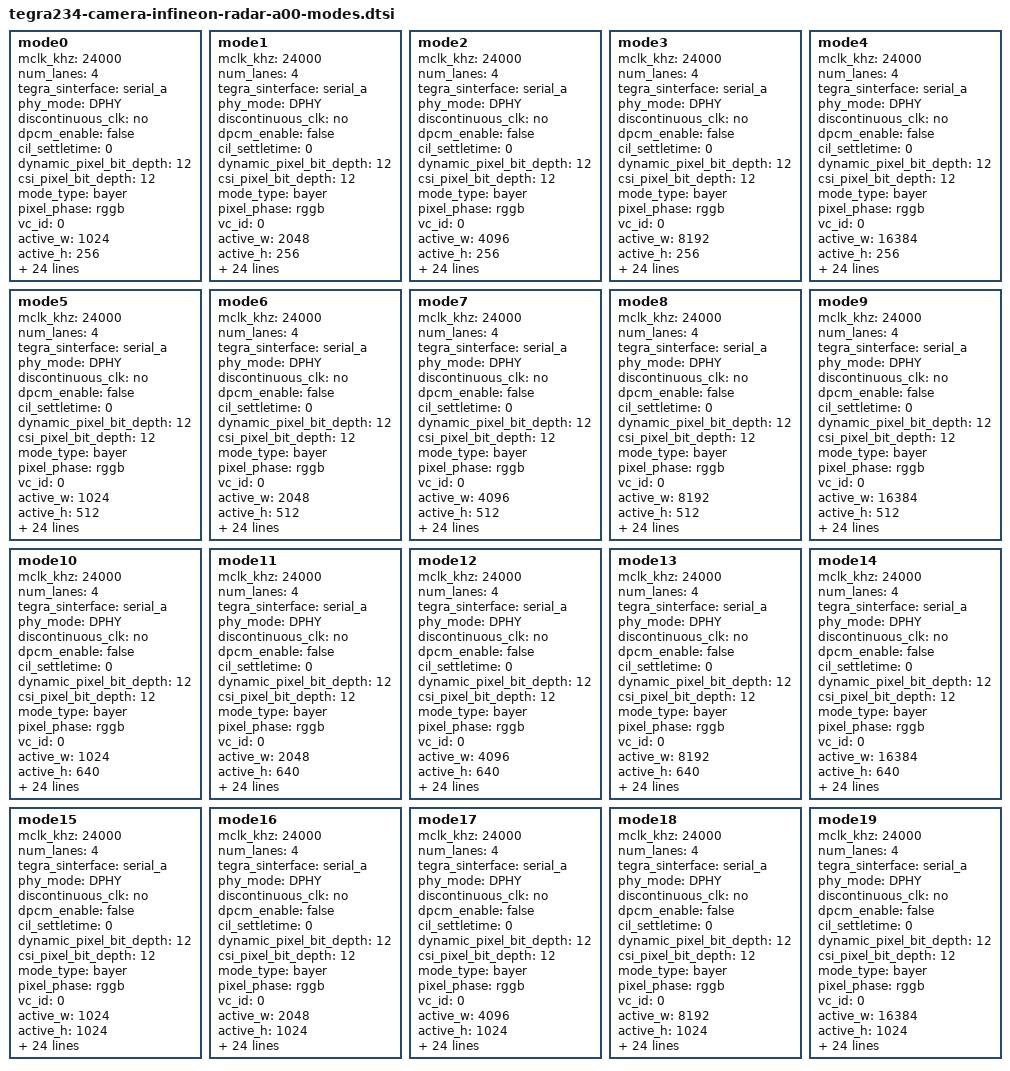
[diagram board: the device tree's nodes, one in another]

/**
* ==== Modes ====
* A modeX node is required to support v4l2 driver
* implementation with NVIDIA camera software stack
*
* == Signal properties ==
*
* phy_mode = "";
* PHY mode used by the MIPI lanes for this device
*
* tegra_sinterface = "";
* CSI Serial interface connected to tegra
* Incase of virtual HW devices, use virtual
* For SW emulated devices, use host
*
* pix_clk_hz = "";
* Sensor pixel clock used for calculations like exposure and framerate
* Not used by the camera stack if serdes_pix_clk_hz is defined
*
* serdes_pix_clk_hz = "";
* Serdes pixel clock used for calculations like exposure and framerate
* It is used when the system includes a serdes system because the data
* is received from the Deserializer
* serdes_pix_clk_hz = (deserializer output data rate in hertz) * (number of CSI lanes) / (bits per pixel)
* 
* readout_orientation = "0";
* Based on camera module orientation.
* Only change readout_orientation if you specifically
* Program a different readout order for this mode
*
* == Image format Properties ==
*
* active_w = "";
* Pixel active region width
*
* active_h = "";
* Pixel active region height
*
* pixel_t = "";
* The sensor readout pixel pattern
*
* line_length = "";
* Pixel line length (width) for sensor mode. Must be greater than or equal to active_w
*
* == Source Control Settings ==
*
* Gain factor used to convert fixed point integer to float
* Gain range [min_gain/gain_factor, max_gain/gain_factor]
* Gain step [step_gain/gain_factor is the smallest step that can be configured]
* Default gain [Default gain to be initialized for the control.
*     use min_gain_val as default for optimal results]
* Framerate factor used to convert fixed point integer to float
* Framerate range [min_framerate/framerate_factor, max_framerate/framerate_factor]
* Framerate step [step_framerate/framerate_factor is the smallest step that can be configured]
* Default Framerate [Default framerate to be initialized for the control.
*     use max_framerate to get required performance]
* Exposure factor used to convert fixed point integer to float
* For convenience use 1 sec = 1000000us as conversion factor
* Exposure range [min_exp_time/exposure_factor, max_exp_time/exposure_factor]
* Exposure step [step_exp_time/exposure_factor is the smallest step that can be configured]
* Default Exposure Time [Default exposure to be initialized for the control.
*     Set default exposure based on the default_framerate for optimal exposure settings]
*
* gain_factor = ""; (integer factor used for floating to fixed point conversion)
* min_gain_val = ""; (ceil to integer)
* max_gain_val = ""; (ceil to integer)
* step_gain_val = ""; (ceil to integer)
* default_gain = ""; (ceil to integer)
* Gain limits for mode
*
* exposure_factor = ""; (integer factor used for floating to fixed point conversion)
* min_exp_time = ""; (ceil to integer)
* max_exp_time = ""; (ceil to integer)
* step_exp_time = ""; (ceil to integer)
* default_exp_time = ""; (ceil to integer)
* Exposure Time limits for mode (sec)
*
* framerate_factor = ""; (integer factor used for floating to fixed point conversion)
* min_framerate = ""; (ceil to integer)
* max_framerate = ""; (ceil to integer)
* step_framerate = ""; (ceil to integer)
* default_framerate = ""; (ceil to integer)
* Framerate limits for mode (fps)
*
* embedded_metadata_height = "";
* Sensor embedded metadata height in units of rows.
* If sensor does not support embedded metadata value should be 0.
*/
mode0 {
    mclk_khz = "24000";
    num_lanes = "4";
    tegra_sinterface = "serial_a";
    phy_mode = "DPHY";
    discontinuous_clk = "no";
    dpcm_enable = "false";
    cil_settletime = "0";
    dynamic_pixel_bit_depth = "12";
    csi_pixel_bit_depth = "12";
    mode_type = "bayer";
    pixel_phase = "rggb";
    vc_id = "0";

    active_w = "1024";
    active_h = "256";
    readout_orientation = "0";
    line_length = "10000";
    inherent_gain = "1";
    mclk_multiplier = "14.58";
    pix_clk_hz = "400000000"; /* Not used if serdes_pix_clk_hz is defined */
    serdes_pix_clk_hz = "400000000";

    gain_factor = "10";
    min_gain_val = "10";
    max_gain_val = "110";
    step_gain_val = "1";
    default_gain = "10";

    min_hdr_ratio = "1";
    max_hdr_ratio = "1";

    framerate_factor = "1000000";
    min_framerate = "30000000"; /* 1.5 */
    max_framerate = "30000000"; /* 30 */
    step_framerate = "1";
    default_framerate= "30000000";

    exposure_factor = "1000000";
    min_exp_time = "30"; /* us */
    max_exp_time = "33000"; /* us */
    step_exp_time = "1";
    default_exp_time = "30000";/* us */
    embedded_metadata_height = "0";
};

mode1 {
    mclk_khz = "24000";
    num_lanes = "4";
    tegra_sinterface = "serial_a";
    phy_mode = "DPHY";
    discontinuous_clk = "no";
    dpcm_enable = "false";
    cil_settletime = "0";
    dynamic_pixel_bit_depth = "12";
    csi_pixel_bit_depth = "12";
    mode_type = "bayer";
    pixel_phase = "rggb";
    vc_id = "0";

    active_w = "2048";
    active_h = "256";
    readout_orientation = "0";
    line_length = "10000";
    inherent_gain = "1";
    mclk_multiplier = "14.58";
    pix_clk_hz = "400000000"; /* Not used if serdes_pix_clk_hz is defined */
    serdes_pix_clk_hz = "400000000";

    gain_factor = "10";
    min_gain_val = "10";
    max_gain_val = "110";
    step_gain_val = "1";
    default_gain = "10";

    min_hdr_ratio = "1";
    max_hdr_ratio = "1";

    framerate_factor = "1000000";
    min_framerate = "30000000"; /* 1.5 */
    max_framerate = "30000000"; /* 30 */
    step_framerate = "1";
    default_framerate= "30000000";

    exposure_factor = "1000000";
    min_exp_time = "30"; /* us */
    max_exp_time = "33000"; /* us */
    step_exp_time = "1";
    default_exp_time = "30000";/* us */
    embedded_metadata_height = "0";
};

mode2 {
    mclk_khz = "24000";
    num_lanes = "4";
    tegra_sinterface = "serial_a";
    phy_mode = "DPHY";
    discontinuous_clk = "no";
    dpcm_enable = "false";
    cil_settletime = "0";
    dynamic_pixel_bit_depth = "12";
    csi_pixel_bit_depth = "12";
    mode_type = "bayer";
    pixel_phase = "rggb";
    vc_id = "0";

    active_w = "4096";
    active_h = "256";
    readout_orientation = "0";
    line_length = "10000";
    inherent_gain = "1";
    mclk_multiplier = "14.58";
    pix_clk_hz = "400000000"; /* Not used if serdes_pix_clk_hz is defined */
    serdes_pix_clk_hz = "400000000";

    gain_factor = "10";
    min_gain_val = "10";
    max_gain_val = "110";
    step_gain_val = "1";
    default_gain = "10";

    min_hdr_ratio = "1";
    max_hdr_ratio = "1";

    framerate_factor = "1000000";
    min_framerate = "30000000"; /* 1.5 */
    max_framerate = "30000000"; /* 30 */
    step_framerate = "1";
    default_framerate= "30000000";

    exposure_factor = "1000000";
    min_exp_time = "30"; /* us */
    max_exp_time = "33000"; /* us */
    step_exp_time = "1";
    default_exp_time = "30000";/* us */
    embedded_metadata_height = "0";
};

mode3 {
    mclk_khz = "24000";
    num_lanes = "4";
    tegra_sinterface = "serial_a";
    phy_mode = "DPHY";
    discontinuous_clk = "no";
    dpcm_enable = "false";
    cil_settletime = "0";
    dynamic_pixel_bit_depth = "12";
    csi_pixel_bit_depth = "12";
    mode_type = "bayer";
    pixel_phase = "rggb";
    vc_id = "0";

    active_w = "8192";
    active_h = "256";
    readout_orientation = "0";
    line_length = "10000";
    inherent_gain = "1";
    mclk_multiplier = "14.58";
    pix_clk_hz = "400000000"; /* Not used if serdes_pix_clk_hz is defined */
    serdes_pix_clk_hz = "400000000";

    gain_factor = "10";
    min_gain_val = "10";
    max_gain_val = "110";
    step_gain_val = "1";
    default_gain = "10";

    min_hdr_ratio = "1";
    max_hdr_ratio = "1";

    framerate_factor = "1000000";
    min_framerate = "30000000"; /* 1.5 */
    max_framerate = "30000000"; /* 30 */
    step_framerate = "1";
    default_framerate= "30000000";

    exposure_factor = "1000000";
    min_exp_time = "30"; /* us */
    max_exp_time = "33000"; /* us */
    step_exp_time = "1";
    default_exp_time = "30000";/* us */
    embedded_metadata_height = "0";
};

mode4 {
    mclk_khz = "24000";
    num_lanes = "4";
    tegra_sinterface = "serial_a";
    phy_mode = "DPHY";
    discontinuous_clk = "no";
    dpcm_enable = "false";
    cil_settletime = "0";
    dynamic_pixel_bit_depth = "12";
    csi_pixel_bit_depth = "12";
    mode_type = "bayer";
    pixel_phase = "rggb";
    vc_id = "0";

    active_w = "16384";
    active_h = "256";
    readout_orientation = "0";
    line_length = "16384";
    inherent_gain = "1";
    mclk_multiplier = "14.58";
    pix_clk_hz = "400000000"; /* Not used if serdes_pix_clk_hz is defined */
    serdes_pix_clk_hz = "400000000";

    gain_factor = "10";
    min_gain_val = "10";
    max_gain_val = "110";
    step_gain_val = "1";
    default_gain = "10";

    min_hdr_ratio = "1";
    max_hdr_ratio = "1";

    framerate_factor = "1000000";
    min_framerate = "30000000"; /* 1.5 */
    max_framerate = "30000000"; /* 30 */
    step_framerate = "1";
    default_framerate= "30000000";

    exposure_factor = "1000000";
    min_exp_time = "30"; /* us */
    max_exp_time = "33000"; /* us */
    step_exp_time = "1";
    default_exp_time = "30000";/* us */
    embedded_metadata_height = "0";
};

mode5 {
    mclk_khz = "24000";
    num_lanes = "4";
    tegra_sinterface = "serial_a";
    phy_mode = "DPHY";
    discontinuous_clk = "no";
    dpcm_enable = "false";
    cil_settletime = "0";
    dynamic_pixel_bit_depth = "12";
    csi_pixel_bit_depth = "12";
    mode_type = "bayer";
    pixel_phase = "rggb";
    vc_id = "0";

    active_w = "1024";
    active_h = "512";
    readout_orientation = "0";
    line_length = "10000";
    inherent_gain = "1";
    mclk_multiplier = "14.58";
    pix_clk_hz = "400000000"; /* Not used if serdes_pix_clk_hz is defined */
    serdes_pix_clk_hz = "400000000";

    gain_factor = "10";
    min_gain_val = "10";
    max_gain_val = "110";
    step_gain_val = "1";
    default_gain = "10";

    min_hdr_ratio = "1";
    max_hdr_ratio = "1";

    framerate_factor = "1000000";
    min_framerate = "30000000"; /* 1.5 */
    max_framerate = "30000000"; /* 30 */
    step_framerate = "1";
    default_framerate= "30000000";

    exposure_factor = "1000000";
    min_exp_time = "30"; /* us */
    max_exp_time = "33000"; /* us */
    step_exp_time = "1";
    default_exp_time = "30000";/* us */
    embedded_metadata_height = "0";
};

mode6 {
    mclk_khz = "24000";
    num_lanes = "4";
    tegra_sinterface = "serial_a";
    phy_mode = "DPHY";
    discontinuous_clk = "no";
    dpcm_enable = "false";
    cil_settletime = "0";
    dynamic_pixel_bit_depth = "12";
    csi_pixel_bit_depth = "12";
    mode_type = "bayer";
    pixel_phase = "rggb";
    vc_id = "0";

    active_w = "2048";
    active_h = "512";
    readout_orientation = "0";
    line_length = "10000";
    inherent_gain = "1";
    mclk_multiplier = "14.58";
    pix_clk_hz = "400000000"; /* Not used if serdes_pix_clk_hz is defined */
    serdes_pix_clk_hz = "400000000";

    gain_factor = "10";
    min_gain_val = "10";
    max_gain_val = "110";
    step_gain_val = "1";
    default_gain = "10";

    min_hdr_ratio = "1";
    max_hdr_ratio = "1";

    framerate_factor = "1000000";
    min_framerate = "30000000"; /* 1.5 */
    max_framerate = "30000000"; /* 30 */
    step_framerate = "1";
    default_framerate= "30000000";

    exposure_factor = "1000000";
    min_exp_time = "30"; /* us */
    max_exp_time = "33000"; /* us */
    step_exp_time = "1";
    default_exp_time = "30000";/* us */
    embedded_metadata_height = "0";
};

mode7 {
    mclk_khz = "24000";
    num_lanes = "4";
    tegra_sinterface = "serial_a";
    phy_mode = "DPHY";
    discontinuous_clk = "no";
    dpcm_enable = "false";
    cil_settletime = "0";
    dynamic_pixel_bit_depth = "12";
    csi_pixel_bit_depth = "12";
    mode_type = "bayer";
    pixel_phase = "rggb";
    vc_id = "0";

    active_w = "4096";
    active_h = "512";
    readout_orientation = "0";
    line_length = "10000";
    inherent_gain = "1";
    mclk_multiplier = "14.58";
    pix_clk_hz = "400000000"; /* Not used if serdes_pix_clk_hz is defined */
    serdes_pix_clk_hz = "400000000";

    gain_factor = "10";
    min_gain_val = "10";
    max_gain_val = "110";
    step_gain_val = "1";
    default_gain = "10";

    min_hdr_ratio = "1";
    max_hdr_ratio = "1";

    framerate_factor = "1000000";
    min_framerate = "30000000"; /* 1.5 */
    max_framerate = "30000000"; /* 30 */
    step_framerate = "1";
    default_framerate= "30000000";

    exposure_factor = "1000000";
    min_exp_time = "30"; /* us */
    max_exp_time = "33000"; /* us */
    step_exp_time = "1";
    default_exp_time = "30000";/* us */
    embedded_metadata_height = "0";
};

mode8 {
    mclk_khz = "24000";
    num_lanes = "4";
    tegra_sinterface = "serial_a";
    phy_mode = "DPHY";
    discontinuous_clk = "no";
    dpcm_enable = "false";
    cil_settletime = "0";
    dynamic_pixel_bit_depth = "12";
    csi_pixel_bit_depth = "12";
    mode_type = "bayer";
    pixel_phase = "rggb";
    vc_id = "0";

    active_w = "8192";
    active_h = "512";
    readout_orientation = "0";
    line_length = "10000";
    inherent_gain = "1";
    mclk_multiplier = "14.58";
    pix_clk_hz = "400000000"; /* Not used if serdes_pix_clk_hz is defined */
    serdes_pix_clk_hz = "400000000";

    gain_factor = "10";
    min_gain_val = "10";
    max_gain_val = "110";
    step_gain_val = "1";
    default_gain = "10";

    min_hdr_ratio = "1";
    max_hdr_ratio = "1";

    framerate_factor = "1000000";
    min_framerate = "30000000"; /* 1.5 */
    max_framerate = "30000000"; /* 30 */
    step_framerate = "1";
    default_framerate= "30000000";

    exposure_factor = "1000000";
    min_exp_time = "30"; /* us */
    max_exp_time = "33000"; /* us */
    step_exp_time = "1";
    default_exp_time = "30000";/* us */
    embedded_metadata_height = "0";
};

mode9 {
    mclk_khz = "24000";
    num_lanes = "4";
    tegra_sinterface = "serial_a";
    phy_mode = "DPHY";
    discontinuous_clk = "no";
    dpcm_enable = "false";
    cil_settletime = "0";
    dynamic_pixel_bit_depth = "12";
    csi_pixel_bit_depth = "12";
    mode_type = "bayer";
    pixel_phase = "rggb";
    vc_id = "0";

    active_w = "16384";
    active_h = "512";
    readout_orientation = "0";
    line_length = "16384";
    inherent_gain = "1";
    mclk_multiplier = "14.58";
    pix_clk_hz = "400000000"; /* Not used if serdes_pix_clk_hz is defined */
    serdes_pix_clk_hz = "400000000";

    gain_factor = "10";
    min_gain_val = "10";
    max_gain_val = "110";
    step_gain_val = "1";
    default_gain = "10";

    min_hdr_ratio = "1";
    max_hdr_ratio = "1";

    framerate_factor = "1000000";
    min_framerate = "30000000"; /* 1.5 */
    max_framerate = "30000000"; /* 30 */
    step_framerate = "1";
    default_framerate= "30000000";

    exposure_factor = "1000000";
    min_exp_time = "30"; /* us */
    max_exp_time = "33000"; /* us */
    step_exp_time = "1";
    default_exp_time = "30000";/* us */
    embedded_metadata_height = "0";
};

mode10 {
    mclk_khz = "24000";
    num_lanes = "4";
    tegra_sinterface = "serial_a";
    phy_mode = "DPHY";
    discontinuous_clk = "no";
    dpcm_enable = "false";
    cil_settletime = "0";
    dynamic_pixel_bit_depth = "12";
    csi_pixel_bit_depth = "12";
    mode_type = "bayer";
    pixel_phase = "rggb";
    vc_id = "0";

    active_w = "1024";
    active_h = "640";
    readout_orientation = "0";
    line_length = "10000";
    inherent_gain = "1";
    mclk_multiplier = "14.58";
    pix_clk_hz = "400000000"; /* Not used if serdes_pix_clk_hz is defined */
    serdes_pix_clk_hz = "400000000";

    gain_factor = "10";
    min_gain_val = "10";
    max_gain_val = "110";
    step_gain_val = "1";
    default_gain = "10";

    min_hdr_ratio = "1";
    max_hdr_ratio = "1";

    framerate_factor = "1000000";
    min_framerate = "30000000"; /* 1.5 */
    max_framerate = "30000000"; /* 30 */
    step_framerate = "1";
    default_framerate= "30000000";

    exposure_factor = "1000000";
    min_exp_time = "30"; /* us */
    max_exp_time = "33000"; /* us */
    step_exp_time = "1";
    default_exp_time = "30000";/* us */
    embedded_metadata_height = "0";
};

mode11 {
    mclk_khz = "24000";
    num_lanes = "4";
    tegra_sinterface = "serial_a";
    phy_mode = "DPHY";
    discontinuous_clk = "no";
    dpcm_enable = "false";
    cil_settletime = "0";
    dynamic_pixel_bit_depth = "12";
    csi_pixel_bit_depth = "12";
    mode_type = "bayer";
    pixel_phase = "rggb";
    vc_id = "0";

    active_w = "2048";
    active_h = "640";
    readout_orientation = "0";
    line_length = "10000";
    inherent_gain = "1";
    mclk_multiplier = "14.58";
    pix_clk_hz = "400000000"; /* Not used if serdes_pix_clk_hz is defined */
    serdes_pix_clk_hz = "400000000";

    gain_factor = "10";
    min_gain_val = "10";
    max_gain_val = "110";
    step_gain_val = "1";
    default_gain = "10";

    min_hdr_ratio = "1";
    max_hdr_ratio = "1";

    framerate_factor = "1000000";
    min_framerate = "30000000"; /* 1.5 */
    max_framerate = "30000000"; /* 30 */
    step_framerate = "1";
    default_framerate= "30000000";

    exposure_factor = "1000000";
    min_exp_time = "30"; /* us */
    max_exp_time = "33000"; /* us */
    step_exp_time = "1";
    default_exp_time = "30000";/* us */
    embedded_metadata_height = "0";
};

mode12 {
    mclk_khz = "24000";
    num_lanes = "4";
    tegra_sinterface = "serial_a";
    phy_mode = "DPHY";
    discontinuous_clk = "no";
    dpcm_enable = "false";
    cil_settletime = "0";
    dynamic_pixel_bit_depth = "12";
    csi_pixel_bit_depth = "12";
    mode_type = "bayer";
    pixel_phase = "rggb";
    vc_id = "0";

    active_w = "4096";
    active_h = "640";
    readout_orientation = "0";
    line_length = "10000";
    inherent_gain = "1";
    mclk_multiplier = "14.58";
    pix_clk_hz = "400000000"; /* Not used if serdes_pix_clk_hz is defined */
    serdes_pix_clk_hz = "400000000";

    gain_factor = "10";
    min_gain_val = "10";
    max_gain_val = "110";
    step_gain_val = "1";
    default_gain = "10";

    min_hdr_ratio = "1";
    max_hdr_ratio = "1";

    framerate_factor = "1000000";
    min_framerate = "30000000"; /* 1.5 */
    max_framerate = "30000000"; /* 30 */
    step_framerate = "1";
    default_framerate= "30000000";

    exposure_factor = "1000000";
    min_exp_time = "30"; /* us */
    max_exp_time = "33000"; /* us */
    step_exp_time = "1";
    default_exp_time = "30000";/* us */
    embedded_metadata_height = "0";
};

mode13 {
    mclk_khz = "24000";
    num_lanes = "4";
    tegra_sinterface = "serial_a";
    phy_mode = "DPHY";
    discontinuous_clk = "no";
    dpcm_enable = "false";
    cil_settletime = "0";
    dynamic_pixel_bit_depth = "12";
    csi_pixel_bit_depth = "12";
    mode_type = "bayer";
    pixel_phase = "rggb";
    vc_id = "0";

    active_w = "8192";
    active_h = "640";
    readout_orientation = "0";
    line_length = "10000";
    inherent_gain = "1";
    mclk_multiplier = "14.58";
    pix_clk_hz = "400000000"; /* Not used if serdes_pix_clk_hz is defined */
    serdes_pix_clk_hz = "400000000";

    gain_factor = "10";
    min_gain_val = "10";
    max_gain_val = "110";
    step_gain_val = "1";
    default_gain = "10";

    min_hdr_ratio = "1";
    max_hdr_ratio = "1";

    framerate_factor = "1000000";
    min_framerate = "30000000"; /* 1.5 */
    max_framerate = "30000000"; /* 30 */
    step_framerate = "1";
    default_framerate= "30000000";

    exposure_factor = "1000000";
    min_exp_time = "30"; /* us */
    max_exp_time = "33000"; /* us */
    step_exp_time = "1";
    default_exp_time = "30000";/* us */
    embedded_metadata_height = "0";
};

mode14 {
    mclk_khz = "24000";
    num_lanes = "4";
    tegra_sinterface = "serial_a";
    phy_mode = "DPHY";
    discontinuous_clk = "no";
    dpcm_enable = "false";
    cil_settletime = "0";
    dynamic_pixel_bit_depth = "12";
    csi_pixel_bit_depth = "12";
    mode_type = "bayer";
    pixel_phase = "rggb";
    vc_id = "0";

    active_w = "16384";
    active_h = "640";
    readout_orientation = "0";
    line_length = "16384";
    inherent_gain = "1";
    mclk_multiplier = "14.58";
    pix_clk_hz = "400000000"; /* Not used if serdes_pix_clk_hz is defined */
    serdes_pix_clk_hz = "400000000";

    gain_factor = "10";
    min_gain_val = "10";
    max_gain_val = "110";
    step_gain_val = "1";
    default_gain = "10";

    min_hdr_ratio = "1";
    max_hdr_ratio = "1";

    framerate_factor = "1000000";
    min_framerate = "30000000"; /* 1.5 */
    max_framerate = "30000000"; /* 30 */
    step_framerate = "1";
    default_framerate= "30000000";

    exposure_factor = "1000000";
    min_exp_time = "30"; /* us */
    max_exp_time = "33000"; /* us */
    step_exp_time = "1";
    default_exp_time = "30000";/* us */
    embedded_metadata_height = "0";
};

mode15 {
    mclk_khz = "24000";
    num_lanes = "4";
    tegra_sinterface = "serial_a";
    phy_mode = "DPHY";
    discontinuous_clk = "no";
    dpcm_enable = "false";
    cil_settletime = "0";
    dynamic_pixel_bit_depth = "12";
    csi_pixel_bit_depth = "12";
    mode_type = "bayer";
    pixel_phase = "rggb";
    vc_id = "0";

    active_w = "1024";
    active_h = "1024";
    readout_orientation = "0";
    line_length = "10000";
    inherent_gain = "1";
    mclk_multiplier = "14.58";
    pix_clk_hz = "400000000"; /* Not used if serdes_pix_clk_hz is defined */
    serdes_pix_clk_hz = "400000000";

    gain_factor = "10";
    min_gain_val = "10";
    max_gain_val = "110";
    step_gain_val = "1";
    default_gain = "10";

    min_hdr_ratio = "1";
    max_hdr_ratio = "1";

    framerate_factor = "1000000";
    min_framerate = "30000000"; /* 1.5 */
    max_framerate = "30000000"; /* 30 */
    step_framerate = "1";
    default_framerate= "30000000";

    exposure_factor = "1000000";
    min_exp_time = "30"; /* us */
    max_exp_time = "33000"; /* us */
    step_exp_time = "1";
    default_exp_time = "30000";/* us */
    embedded_metadata_height = "0";
};

mode16 {
    mclk_khz = "24000";
    num_lanes = "4";
    tegra_sinterface = "serial_a";
    phy_mode = "DPHY";
    discontinuous_clk = "no";
    dpcm_enable = "false";
    cil_settletime = "0";
    dynamic_pixel_bit_depth = "12";
    csi_pixel_bit_depth = "12";
    mode_type = "bayer";
    pixel_phase = "rggb";
    vc_id = "0";

    active_w = "2048";
    active_h = "1024";
    readout_orientation = "0";
    line_length = "10000";
    inherent_gain = "1";
    mclk_multiplier = "14.58";
    pix_clk_hz = "400000000"; /* Not used if serdes_pix_clk_hz is defined */
    serdes_pix_clk_hz = "400000000";

    gain_factor = "10";
    min_gain_val = "10";
    max_gain_val = "110";
    step_gain_val = "1";
    default_gain = "10";

    min_hdr_ratio = "1";
    max_hdr_ratio = "1";

    framerate_factor = "1000000";
    min_framerate = "30000000"; /* 1.5 */
    max_framerate = "30000000"; /* 30 */
    step_framerate = "1";
    default_framerate= "30000000";

    exposure_factor = "1000000";
    min_exp_time = "30"; /* us */
    max_exp_time = "33000"; /* us */
    step_exp_time = "1";
    default_exp_time = "30000";/* us */
    embedded_metadata_height = "0";
};

mode17 {
    mclk_khz = "24000";
    num_lanes = "4";
    tegra_sinterface = "serial_a";
    phy_mode = "DPHY";
    discontinuous_clk = "no";
    dpcm_enable = "false";
    cil_settletime = "0";
    dynamic_pixel_bit_depth = "12";
    csi_pixel_bit_depth = "12";
    mode_type = "bayer";
    pixel_phase = "rggb";
    vc_id = "0";

    active_w = "4096";
    active_h = "1024";
    readout_orientation = "0";
    line_length = "10000";
    inherent_gain = "1";
    mclk_multiplier = "14.58";
    pix_clk_hz = "400000000"; /* Not used if serdes_pix_clk_hz is defined */
    serdes_pix_clk_hz = "400000000";

    gain_factor = "10";
    min_gain_val = "10";
    max_gain_val = "110";
    step_gain_val = "1";
    default_gain = "10";

    min_hdr_ratio = "1";
    max_hdr_ratio = "1";

    framerate_factor = "1000000";
    min_framerate = "30000000"; /* 1.5 */
    max_framerate = "30000000"; /* 30 */
    step_framerate = "1";
    default_framerate= "30000000";

    exposure_factor = "1000000";
    min_exp_time = "30"; /* us */
    max_exp_time = "33000"; /* us */
    step_exp_time = "1";
    default_exp_time = "30000";/* us */
    embedded_metadata_height = "0";
};

mode18 {
    mclk_khz = "24000";
    num_lanes = "4";
    tegra_sinterface = "serial_a";
    phy_mode = "DPHY";
    discontinuous_clk = "no";
    dpcm_enable = "false";
    cil_settletime = "0";
    dynamic_pixel_bit_depth = "12";
    csi_pixel_bit_depth = "12";
    mode_type = "bayer";
    pixel_phase = "rggb";
    vc_id = "0";

    active_w = "8192";
    active_h = "1024";
    readout_orientation = "0";
    line_length = "10000";
    inherent_gain = "1";
    mclk_multiplier = "14.58";
    pix_clk_hz = "400000000"; /* Not used if serdes_pix_clk_hz is defined */
    serdes_pix_clk_hz = "400000000";

    gain_factor = "10";
    min_gain_val = "10";
    max_gain_val = "110";
    step_gain_val = "1";
    default_gain = "10";

    min_hdr_ratio = "1";
    max_hdr_ratio = "1";

    framerate_factor = "1000000";
    min_framerate = "30000000"; /* 1.5 */
    max_framerate = "30000000"; /* 30 */
    step_framerate = "1";
    default_framerate= "30000000";

    exposure_factor = "1000000";
    min_exp_time = "30"; /* us */
    max_exp_time = "33000"; /* us */
    step_exp_time = "1";
    default_exp_time = "30000";/* us */
    embedded_metadata_height = "0";
};

mode19 {
    mclk_khz = "24000";
    num_lanes = "4";
    tegra_sinterface = "serial_a";
    phy_mode = "DPHY";
    discontinuous_clk = "no";
    dpcm_enable = "false";
    cil_settletime = "0";
    dynamic_pixel_bit_depth = "12";
    csi_pixel_bit_depth = "12";
    mode_type = "bayer";
    pixel_phase = "rggb";
    vc_id = "0";

    active_w = "16384";
    active_h = "1024";
    readout_orientation = "0";
    line_length = "16384";
    inherent_gain = "1";
    mclk_multiplier = "14.58";
    pix_clk_hz = "400000000"; /* Not used if serdes_pix_clk_hz is defined */
    serdes_pix_clk_hz = "400000000";

    gain_factor = "10";
    min_gain_val = "10";
    max_gain_val = "110";
    step_gain_val = "1";
    default_gain = "10";

    min_hdr_ratio = "1";
    max_hdr_ratio = "1";

    framerate_factor = "1000000";
    min_framerate = "30000000"; /* 1.5 */
    max_framerate = "30000000"; /* 30 */
    step_framerate = "1";
    default_framerate= "30000000";

    exposure_factor = "1000000";
    min_exp_time = "30"; /* us */
    max_exp_time = "33000"; /* us */
    step_exp_time = "1";
    default_exp_time = "30000";/* us */
    embedded_metadata_height = "0";
};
